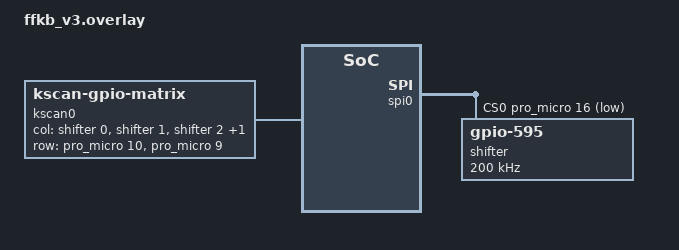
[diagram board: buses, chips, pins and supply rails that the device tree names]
#include <dt-bindings/zmk/matrix_transform.h>

&spi0 {
    status = "okay";
    compatible = "raspberrypi,pico-spi";
    pinctrl-0 = <&spi0_default>;
    pinctrl-names = "default";
    cs-gpios = <&pro_micro 16 GPIO_ACTIVE_LOW>;

    shifter: 595@0 {
        compatible = "zmk,gpio-595";
        status = "okay";
        gpio-controller;
        spi-max-frequency = <200000>;
        reg = <0>;
        #gpio-cells = <2>;
        ngpios = <8>;
    };
};

/ {
    kscan0: kscan_0 {
        compatible = "zmk,kscan-gpio-matrix";
        wakeup-source;
        diode-direction = "col2row";

        col-gpios
            = <&shifter 0 GPIO_ACTIVE_HIGH>
            , <&shifter 1 GPIO_ACTIVE_HIGH>
            , <&shifter 2 GPIO_ACTIVE_HIGH>
            , <&shifter 3 GPIO_ACTIVE_HIGH>
            ;

        row-gpios
            = <&pro_micro 10 (GPIO_ACTIVE_HIGH | GPIO_PULL_DOWN)>
            , <&pro_micro 9  (GPIO_ACTIVE_HIGH | GPIO_PULL_DOWN)>
            ;
    };
};
